# busSlave: IP-XACT component
VLNV tut.fi:ip.testcomponents:busSlave:1.0

## Bus interfaces (logical=physical port)
bus_slave: slave librecores.org:wishbone:wishbone:b3, memory map slaveMap
  ack_i=ack_i, adr_o[31:0]=adr_o[31:0], bte_o[1:0]=bte_o[1:0], cti_o[2:0]=cti_o[2:0], cyc_o[0:0]=cyc_o[0:0], dat_i[31:0]=dat_i[31:0], dat_o=dat_o, err_i[0:0]=err_i[0:0], rty_i[0:0]=rty_i[0:0], sel_o[3:0]=sel_o[3:0], stb_o[0:0]=stb_o[0:0], we_o[0:0]=we_o[0:0]

## Ports
out ack_i[0:0]
in adr_o[31:0]
in bte_o[1:0]
in cti_o[2:0]
in cyc_o[0:0]
out dat_i[31:0]
in dat_o[31:0]
out err_i[0:0]
out rty_i[0:0]
in sel_o[3:0]
in stb_o[0:0]
in we_o[0:0]
in config[3:0]

## Address spaces and blocks
slaveMap.registers: base 'h0, range 4, width 32, register
slaveMap.registers: base 'h0, range 4, width 32, register
slaveMap.registers: base 'h0, range 4, width 32, register

## Registers
Registers are 32-bit, access not given, no defined reset value unless marked. A register's access mark holds for its fields unless they carry their own. Offsets are from the block's base; lines under a group give offsets from that group; [hi:lo] are bit positions; {n}, {i} and the like mark numbered series; 'fields as' and 'values as' point back to an identical list; <NAME> marks a mode.

## slaveMap.registers
Base 0x00000000
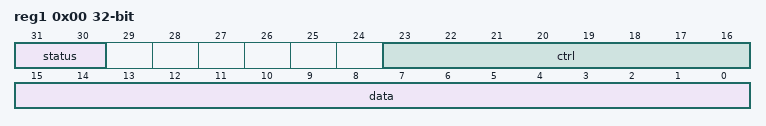
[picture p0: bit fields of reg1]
0x00 reg1
  [31:0] data

## slaveMap.registers
Base 0x00000000
{0x0+2i} reg1[{i}] (i=0..1) 16-bit
  [15:0] data

## slaveMap.registers
Base 0x00000000
0x00 reg1
  [31:30] status, [23:16] ctrl, [15:0] data
